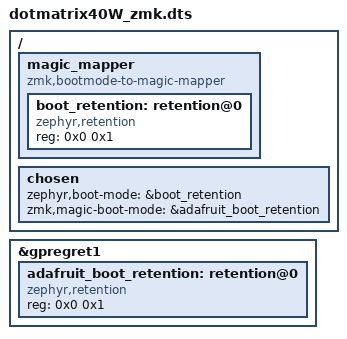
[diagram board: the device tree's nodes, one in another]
/*
 * Copyright (c) 2021 Nick Winans
 * Copyright (c) 2024
 * Copyright 2026 Tano Karbou (github: karbou12 / X: @karbou_12)
 *
 * SPDX-License-Identifier: MIT
 */

#include "dotmatrix40W.dts"
#include <common/nordic/nrf52840_uf2_boot_mode.dtsi>

&gpregret1 {
    adafruit_boot_retention: retention@0 {
        compatible = "zephyr,retention";
        status = "okay";
        reg = <0x0 0x1>;
    };
};

/ {
    magic_mapper {
        compatible = "zmk,bootmode-to-magic-mapper";
        status = "okay";

        #address-cells = <1>;
        #size-cells = <1>;

        boot_retention: retention@0 {
            compatible = "zephyr,retention";
            status = "okay";
            reg = <0x0 0x1>;
        };
    };

    chosen {
        zephyr,boot-mode = &boot_retention;
        zmk,magic-boot-mode = &adafruit_boot_retention;
    };
};
